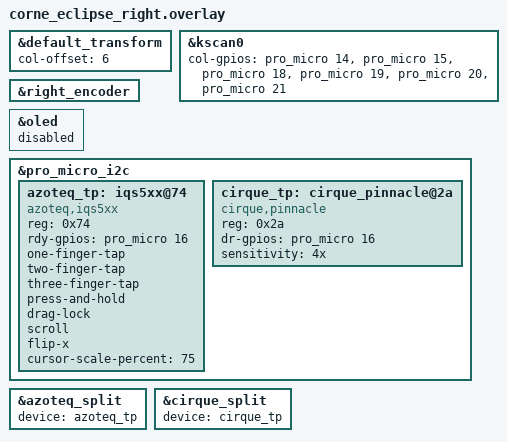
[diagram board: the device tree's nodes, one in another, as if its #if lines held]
/*
 * Copyright (c) 2020 Pete Johanson
 *
 * SPDX-License-Identifier: MIT
 */

#include "corne_eclipse.dtsi"

&default_transform {
    col-offset = <6>;
};

/*
&five_column_transform {
    col-offset = <6>;
};
*/

&kscan0 {
    col-gpios
        = <&pro_micro 14 GPIO_ACTIVE_HIGH>
        , <&pro_micro 15 GPIO_ACTIVE_HIGH>
        , <&pro_micro 18 GPIO_ACTIVE_HIGH>
        , <&pro_micro 19 GPIO_ACTIVE_HIGH>
        , <&pro_micro 20 GPIO_ACTIVE_HIGH>
        , <&pro_micro 21 GPIO_ACTIVE_HIGH>
        ;
};

/* Encoder is always enabled. With pad 14 (SPI_SCK net = D16 = P0.10) used
 * for trackpad RDY/DR, the encoder on pads 11/12 (D8/D9) coexists with a
 * trackpad. Whether the encoder is actually populated is purely a
 * hand-population choice. */
&right_encoder {
    status = "okay";
};

#ifdef TRACKPAD_PERIPHERAL

/* This (peripheral) half physically hosts the trackpad. The nice!view
 * display is electrically incompatible with it: nice!view's SPI0 uses the
 * same P0.17/P0.20 pins the trackpad needs for I2C, so the display is
 * disabled here. */
&oled {
    status = "disabled";
};

/* Both trackpad device nodes are defined so one firmware auto-detects
 * whichever module is wired: the I2C device that doesn't respond fails to
 * probe and stays silent. Both expect their RDY/DR signal on pad 14
 * (SPI_SCK net = D16 = P0.10). */
&pro_micro_i2c {
    azoteq_tp: iqs5xx@74 {
        compatible = "azoteq,iqs5xx";
        reg = <0x74>;
        rdy-gpios = <&pro_micro 16 GPIO_ACTIVE_HIGH>;
        one-finger-tap;
        two-finger-tap;
        three-finger-tap;
        press-and-hold;
        drag-lock;
        scroll;
        /* zoom; -- disabled: the 43mm pad is too small for the chip to detect a
         * pinch reliably, and at sensitive thresholds it steals scroll. */
        flip-x;
        cursor-scale-percent = <75>;
    };

    cirque_tp: cirque_pinnacle@2a {
        compatible = "cirque,pinnacle";
        reg = <0x2a>; /* 0x2c if the module's R1 jumper is bridged */
        dr-gpios = <&pro_micro 16 GPIO_ACTIVE_HIGH>;
        sensitivity = "4x";
    };
};

/* Forward the local trackpad to the central over the split link. The
 * input-split proxy nodes and their (disabled) listeners live in the shared
 * .dtsi; here we attach each physical device to its proxy. The central
 * enables the matching listener. A plain input-listener on the peripheral
 * would NOT reach the host -- peripheral pointing requires input-split. */
&azoteq_split {
    device = <&azoteq_tp>;
};

&cirque_split {
    device = <&cirque_tp>;
};

#endif /* TRACKPAD_PERIPHERAL */
